AUTOSAR XML (schema 4-0-3)
standard types defined: Boolean, UInt16, UInt32, UInt8
package /AUTOSAR_Platform/DataConstrs
  range DC_Boolean: raw 0..1
  range DC_UInt16: raw 0..65535
  range DC_UInt8: raw 0..255
package /PATAC/MSM/ComponentTypes
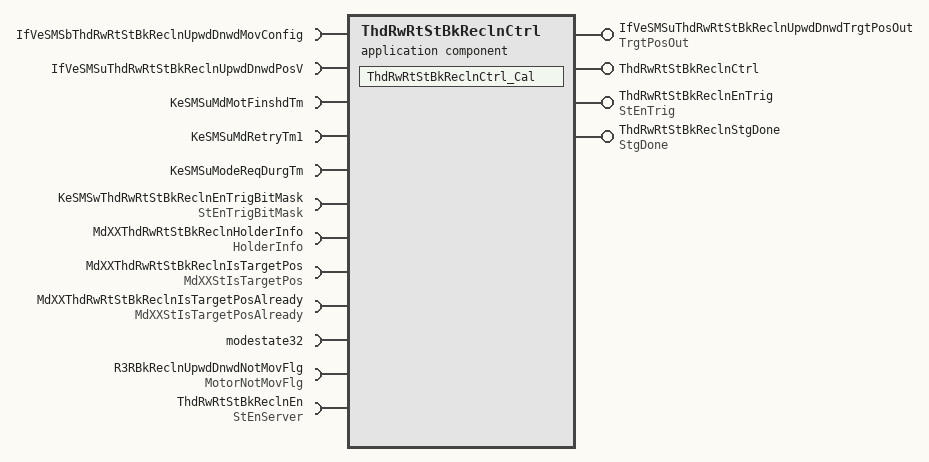
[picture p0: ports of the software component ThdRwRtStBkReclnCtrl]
  application sw component type ThdRwRtStBkReclnCtrl
    4 x provide port:
      IfVeSMSuThdRwRtStBkReclnUpwdDnwdTrgtPosOut: nonqueued-sender-com-spec{data-element=TrgtPosOut/Val, init-value=0}, provided-interface=TrgtPosOut
      ThdRwRtStBkReclnCtrl: server-com-spec{operation=Cal, queue-length=1}, provided-interface=ThdRwRtStBkReclnCtrl
      ThdRwRtStBkReclnEnTrig: nonqueued-sender-com-spec{data-element=StEnTrig/Val, init-value=0}, provided-interface=StEnTrig
      ThdRwRtStBkReclnStgDone: nonqueued-sender-com-spec{data-element=StgDone/Val, init-value=0}, provided-interface=StgDone
    12 x require port:
      IfVeSMSbThdRwRtStBkReclnUpwdDnwdMovConfig: nonqueued-receiver-com-spec{data-element=IfVeSMSbThdRwRtStBkReclnUpwdDnwdMovConfig/Val, filter=data-filter-type=ALWAYS, init-value=0}, required-interface=IfVeSMSbThdRwRtStBkReclnUpwdDnwdMovConfig
      IfVeSMSuThdRwRtStBkReclnUpwdDnwdPosV: nonqueued-receiver-com-spec{data-element=IfVeSMSuThdRwRtStBkReclnUpwdDnwdPosV/Val, filter=data-filter-type=ALWAYS, init-value=0}, required-interface=IfVeSMSuThdRwRtStBkReclnUpwdDnwdPosV
      KeSMSuMdMotFinshdTm: parameter-require-com-spec{init-value=0, parameter=KeSMSuMdMotFinshdTm/Val}, required-interface=KeSMSuMdMotFinshdTm
      KeSMSuMdRetryTm1: parameter-require-com-spec{init-value=0, parameter=KeSMSuMdRetryTm1/Val}, required-interface=KeSMSuMdRetryTm1
      KeSMSuModeReqDurgTm: parameter-require-com-spec{init-value=0, parameter=KeSMSuModeReqDurgTm/Val}, required-interface=KeSMSuModeReqDurgTm
      KeSMSwThdRwRtStBkReclnEnTrigBitMask: parameter-require-com-spec{init-value=6153, parameter=StEnTrigBitMask/Val}, required-interface=StEnTrigBitMask
      MdXXThdRwRtStBkReclnHolderInfo: nonqueued-receiver-com-spec{data-element=HolderInfo/Val, filter=data-filter-type=ALWAYS, init-value=0}, required-interface=HolderInfo
      MdXXThdRwRtStBkReclnIsTargetPos: nonqueued-receiver-com-spec{data-element=MdXXStIsTargetPos/Val, filter=data-filter-type=ALWAYS, init-value=0}, required-interface=MdXXStIsTargetPos
      MdXXThdRwRtStBkReclnIsTargetPosAlready: nonqueued-receiver-com-spec{data-element=MdXXStIsTargetPosAlready/Val, filter=data-filter-type=ALWAYS, init-value=0}, required-interface=MdXXStIsTargetPosAlready
      modestate32: nonqueued-receiver-com-spec{data-element=modestate32/Val, filter=data-filter-type=ALWAYS, init-value=0}, required-interface=modestate32
      R3RBkReclnUpwdDnwdNotMovFlg: nonqueued-receiver-com-spec{data-element=MotorNotMovFlg/Val, filter=data-filter-type=ALWAYS, init-value=0}, required-interface=MotorNotMovFlg
      ThdRwRtStBkReclnEn: required-com-specs=[Clear, Get, Set], required-interface=StEnServer
    behavior ThdRwRtStBkReclnCtrl_InternalBehavior
      operation invoked event OIT_ThdRwRtStBkReclnCtrl_Cal_ThdRwRtStBkReclnCtrl_Cal: start-on-event=ThdRwRtStBkReclnCtrl_Cal, operation=ThdRwRtStBkReclnCtrl.Cal
      runnable ThdRwRtStBkReclnCtrl_Cal
        data-receive-point-by-arguments:
          7 x access:
            REC_IfVeSMSbThdRwRtStBkReclnUpwdDnwdMovConfig_Val: accessed-variable=IfVeSMSbThdRwRtStBkReclnUpwdDnwdMovConfig.Val
            REC_IfVeSMSuThdRwRtStBkReclnUpwdDnwdPosV_Val: accessed-variable=IfVeSMSuThdRwRtStBkReclnUpwdDnwdPosV.Val
            REC_MdXXThdRwRtStBkReclnHolderInfo_Val: accessed-variable=MdXXThdRwRtStBkReclnHolderInfo.Val
            REC_MdXXThdRwRtStBkReclnIsTargetPos_Val: accessed-variable=MdXXThdRwRtStBkReclnIsTargetPos.Val
            REC_MdXXThdRwRtStBkReclnIsTargetPosAlready_Val: accessed-variable=MdXXThdRwRtStBkReclnIsTargetPosAlready.Val
            REC_modestate32_Val: accessed-variable=modestate32.Val
            REC_R3RBkReclnUpwdDnwdNotMovFlg_Val: accessed-variable=R3RBkReclnUpwdDnwdNotMovFlg.Val
        data-send-points:
          access SEND_IfVeSMSuThdRwRtStBkReclnUpwdDnwdTrgtPosOut_Val: accessed-variable=IfVeSMSuThdRwRtStBkReclnUpwdDnwdTrgtPosOut.Val
          access SEND_ThdRwRtStBkReclnEnTrig_Val: accessed-variable=ThdRwRtStBkReclnEnTrig.Val
          access SEND_ThdRwRtStBkReclnStgDone_Val: accessed-variable=ThdRwRtStBkReclnStgDone.Val
        4 x parameter access:
          PA_KeSMSuMdMotFinshdTm_Val: accessed-parameter=KeSMSuMdMotFinshdTm.Val
          PA_KeSMSuMdRetryTm1_Val: accessed-parameter=KeSMSuMdRetryTm1.Val
          PA_KeSMSuModeReqDurgTm_Val: accessed-parameter=KeSMSuModeReqDurgTm.Val
          PA_KeSMSwThdRwRtStBkReclnEnTrigBitMask_Val: accessed-parameter=KeSMSwThdRwRtStBkReclnEnTrigBitMask.Val
        sync call SC_ThdRwRtStBkReclnEn_Get: operation=ThdRwRtStBkReclnEn.Get, timeout=0
  swc implementation ThdRwRtStBkReclnCtrl_Implementation: behavior=ThdRwRtStBkReclnCtrl_InternalBehavior
    code-descriptors:
      code Default: artifact-descriptors=autosar-engineering-object={short-label=Default, category=SWSRC}
package /PATAC/MSM/ModeAdjust/CalPortInterface
  parameter interface KeSMSuMdMotFinshdTm
    parameter data prototype Val: sw-calibration-access=READ-WRITE, type=UInt16
  parameter interface KeSMSuModeReqDurgTm
    parameter data prototype Val: sw-calibration-access=READ-WRITE, type=UInt16
  parameter interface StEnTrigBitMask
    parameter data prototype Val: sw-calibration-access=READ-WRITE, type=UInt32
package /PATAC/MSM/ModeAdjust/Interfaces
  sender receiver interface IfVeSMSuThdRwRtStBkReclnUpwdDnwdPosV: invalidation-policy{data-element=IfVeSMSuThdRwRtStBkReclnUpwdDnwdPosV/Val, handle-invalid=DONT-INVALIDATE}
    data Val: type=Boolean
package /PATAC/MSM/ModeAdjust/PortInterface
  client server interface StEnServer
    operation Clear
      arg data: type=UInt8, direction=IN, server-argument-impl-policy=USE-ARGUMENT-TYPE
    operation Get
      arg data: type=UInt32, direction=OUT, server-argument-impl-policy=USE-ARGUMENT-TYPE
    operation Set
      arg data: type=UInt8, direction=IN, server-argument-impl-policy=USE-ARGUMENT-TYPE
  client server interface ThdRwRtStBkReclnCtrl
    operation Cal
  8 x sender receiver interface:
    HolderInfo: invalidation-policy{data-element=HolderInfo/Val, handle-invalid=DONT-INVALIDATE}
      data Val: type=UInt32
    MdXXStIsTargetPos: invalidation-policy{data-element=MdXXStIsTargetPos/Val, handle-invalid=DONT-INVALIDATE}
      data Val: type=UInt32
    MdXXStIsTargetPosAlready: invalidation-policy{data-element=MdXXStIsTargetPosAlready/Val, handle-invalid=DONT-INVALIDATE}
      data Val: type=UInt32
    modestate32: invalidation-policy{data-element=modestate32/Val, handle-invalid=DONT-INVALIDATE}
      data Val: type=UInt32
    MotorNotMovFlg: invalidation-policy{data-element=MotorNotMovFlg/Val, handle-invalid=DONT-INVALIDATE}
      data Val: type=Boolean
    StEnTrig: invalidation-policy{data-element=StEnTrig/Val, handle-invalid=DONT-INVALIDATE}
      data Val: type=Boolean
    StgDone: invalidation-policy{data-element=StgDone/Val, handle-invalid=DONT-INVALIDATE}
      data Val: type=Boolean
    TrgtPosOut: invalidation-policy{data-element=TrgtPosOut/Val, handle-invalid=DONT-INVALIDATE}
      data Val: type=Boolean
package /PATAC/MSM/PortInterfaces
  parameter interface KeSMSuMdRetryTm1
    parameter data prototype Val: sw-calibration-access=READ-WRITE, type=UInt8
  sender receiver interface IfVeSMSbThdRwRtStBkReclnUpwdDnwdMovConfig: invalidation-policy{data-element=IfVeSMSbThdRwRtStBkReclnUpwdDnwdMovConfig/Val, handle-invalid=DONT-INVALIDATE}
    data Val: type=Boolean
